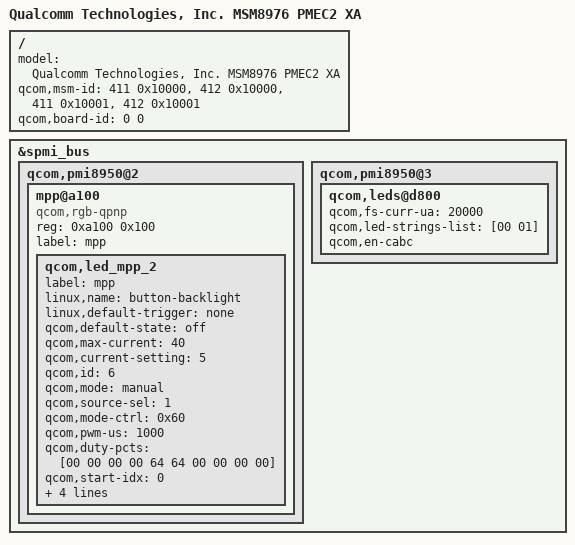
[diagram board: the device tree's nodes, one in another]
/*
 * Copyright (c) 2015, The Linux Foundation. All rights reserved.
 *
 * This program is free software; you can redistribute it and/or modify
 * it under the terms of the GNU General Public License version 2 and
 * only version 2 as published by the Free Software Foundation.
 *
 * This program is distributed in the hope that it will be useful,
 * but WITHOUT ANY WARRANTY; without even the implied warranty of
 * MERCHANTABILITY or FITNESS FOR A PARTICULAR PURPOSE.  See the
 * GNU General Public License for more details.
 */

/dts-v1/;

#include "msm8976-v1.1.dtsi"
#include "msm8976-htc_pmec2.dtsi"
//HTC_CAM_START, camera dtsi for XA board
#include "msm8976-camera-sensor-pmec2.dtsi"
//HTC_CAM_END

&spmi_bus {
	qcom,pmi8950@2 {
		mpp@a100 { /* MPP 2 */
			compatible = "qcom,rgb-qpnp";
			reg = <0xa100 0x100>;
			label = "mpp";
			status = "okay";
			qcom,led_mpp_2 {
				label = "mpp";
				linux,name = "button-backlight";
				linux,default-trigger = "none";
				//pwms = <&pmi8994_pwm_4 0 0>;
				qcom,default-state = "off";
				qcom,max-current = <40>;
				qcom,current-setting = <5>;
				qcom,id = <6>;
				qcom,mode = "manual";
				qcom,source-sel = <1>;
				qcom,mode-ctrl = <0x60>;
				qcom,pwm-us = <1000>;
				qcom,duty-pcts = [00 00 00 00 64
									64 00 00 00 00];
				qcom,start-idx = <0>;
				qcom,pause-hi = <1>;
				qcom,pause-lo = <1>;
				qcom,ramp-step-ms = <64>;
				qcom,lut-flags = <0x18>;
			};
		};
	};
	qcom,pmi8950@3 {
		qcom,leds@d800 {
			qcom,fs-curr-ua = <20000>;      /* HTC: 2ch, 20mA */
			qcom,led-strings-list = [00 01];
			qcom,en-cabc;
		};
	};
};


/ {
	model = "Qualcomm Technologies, Inc. MSM8976 PMEC2 XA";
	qcom,msm-id = <411 0x10000>, <412 0x10000>, <411 0x10001>, <412 0x10001>;
	qcom,board-id= <0 0>;
};
